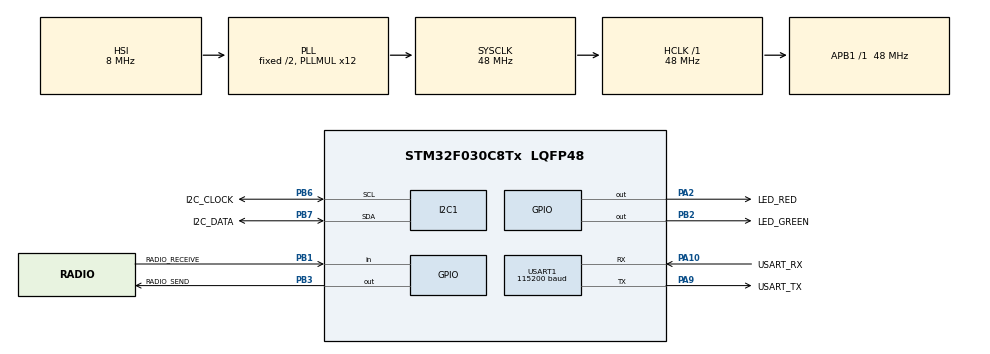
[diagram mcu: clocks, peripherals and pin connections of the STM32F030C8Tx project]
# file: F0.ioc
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Mcu.Family=STM32F0
USART1.BaudRate=115200
PA14.GPIO_Label=SWD_CLOCK
PB2.GPIO_Speed=GPIO_SPEED_FREQ_HIGH
PA2.GPIO_Speed=GPIO_SPEED_FREQ_HIGH
VP_RTC_VS_RTC_Activate.Mode=RTC_Enabled
PB6.GPIO_Label=I2C_CLOCK
RCC.SYSCLKSource=RCC_SYSCLKSOURCE_PLLCLK
ProjectManager.StackSize=0x400
TIM15.Prescaler=480
RCC.HCLKFreq_Value=48000000
PB6.Signal=I2C1_SCL
PB6.Mode=I2C
RCC.AHBFreq_Value=48000000
PB2.Signal=GPIO_Output
RCC.PLLMUL=RCC_PLL_MUL12
TIM15.Period=99
PA14.Mode=Serial_Wire
PB1.GPIO_Label=RADIO_RECEIVE
PA10.GPIO_Label=USART_RX
PB7.Signal=I2C1_SDA
PB7.GPIO_Label=I2C_DATA
Mcu.Package=LQFP48
PB1.Signal=GPIO_Input
PA2.GPIO_Label=LED_RED
PA10.Signal=USART1_RX
VP_RTC_VS_RTC_Calendar.Mode=RTC_Calendar
RCC.APB1TimFreq_Value=48000000
TIM16.Prescaler=48
NVIC.TIM15_IRQn=true\:0\:0\:false\:false\:true\:true\:true
PB3.GPIO_Label=RADIO_SEND
PA10.Mode=Asynchronous
PA9.GPIO_Label=USART_TX
VP_TIM16_VS_ClockSourceINT.Mode=Enable_Timer
NVIC.TIM16_IRQn=true\:0\:0\:false\:false\:true\:true\:true
USART1.VirtualMode-Asynchronous=VM_ASYNC
PA13.Signal=SYS_SWDIO
PA9.Mode=Asynchronous
ProjectManager.TargetToolchain=STM32CubeIDE
PA9.Signal=USART1_TX
I2C1.Timing=0x20303E5D
board=custom
TIM16.Period=9
RCC.I2c1ClockSelection=RCC_I2C1CLKSOURCE_SYSCLK
PA13.Mode=Serial_Wire
Mcu.Name=STM32F030C8Tx
PA13.GPIO_Label=SWD_IO
PA2.Signal=GPIO_Output
PB3.Signal=GPIO_Output
RCC.SYSCLKFreq_VALUE=48000000
PB7.Mode=I2C
VP_TIM15_VS_ClockSourceINT.Mode=Internal
PA14.Signal=SYS_SWCLK
PB2.GPIO_Label=LED_GREEN
ProjectManager.HeapSize=0x200
RCC.APB1Freq_Value=48000000

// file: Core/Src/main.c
/* USER CODE BEGIN Header */
/**
 ******************************************************************************
 * @file           : main.c
 * @brief          : Main program body
 ******************************************************************************
 * @attention
 *
 * <h2><center>&copy; Copyright (c) 2021 STMicroelectronics.
 * All rights reserved.</center></h2>
 *
 * This software component is licensed by ST under BSD 3-Clause license,
 * the "License"; You may not use this file except in compliance with the
 * License. You may obtain a copy of the License at:
 *                        opensource.org/licenses/BSD-3-Clause
 *
 ******************************************************************************
 */
/* USER CODE END Header */
#include "main.h"
#include "i2c.h"
#include "rtc.h"
#include "tim.h"
#include "usart.h"
#include "gpio.h"

/* USER CODE BEGIN Includes */

#include "RATmain.h"

/* USER CODE END Includes */

void SystemClock_Config(void);

int main(void)
{

  /* MCU Configuration--------------------------------------------------------*/

  /* Reset of all peripherals, Initializes the Flash interface and the Systick. */
  HAL_Init();

  /* Configure the system clock */
  SystemClock_Config();

  /* Initialize all configured peripherals */
  MX_GPIO_Init();
  MX_I2C1_Init();
  MX_USART1_UART_Init();
  MX_RTC_Init();
  MX_TIM15_Init();
  MX_TIM16_Init();
  /* USER CODE BEGIN 2 */

  //Own main file, for readabillity
  RATmain();

  /* USER CODE END 2 */

  /* Infinite loop */
	while (1)
	{

	}
}

void SystemClock_Config(void)
{
  RCC_OscInitTypeDef RCC_OscInitStruct = {0};
  RCC_ClkInitTypeDef RCC_ClkInitStruct = {0};
  RCC_PeriphCLKInitTypeDef PeriphClkInit = {0};

  /** Initializes the RCC Oscillators according to the specified parameters
  * in the RCC_OscInitTypeDef structure.
  */
  RCC_OscInitStruct.OscillatorType = RCC_OSCILLATORTYPE_HSI|RCC_OSCILLATORTYPE_LSI;
  RCC_OscInitStruct.HSIState = RCC_HSI_ON;
  RCC_OscInitStruct.HSICalibrationValue = RCC_HSICALIBRATION_DEFAULT;
  RCC_OscInitStruct.LSIState = RCC_LSI_ON;
  RCC_OscInitStruct.PLL.PLLState = RCC_PLL_ON;
  RCC_OscInitStruct.PLL.PLLSource = RCC_PLLSOURCE_HSI;
  RCC_OscInitStruct.PLL.PLLMUL = RCC_PLL_MUL12;
  RCC_OscInitStruct.PLL.PREDIV = RCC_PREDIV_DIV1;
  if (HAL_RCC_OscConfig(&RCC_OscInitStruct) != HAL_OK)
  {
    Error_Handler();
  }
  /** Initializes the CPU, AHB and APB buses clocks
  */
  RCC_ClkInitStruct.ClockType = RCC_CLOCKTYPE_HCLK|RCC_CLOCKTYPE_SYSCLK
                              |RCC_CLOCKTYPE_PCLK1;
  RCC_ClkInitStruct.SYSCLKSource = RCC_SYSCLKSOURCE_PLLCLK;
  RCC_ClkInitStruct.AHBCLKDivider = RCC_SYSCLK_DIV1;
  RCC_ClkInitStruct.APB1CLKDivider = RCC_HCLK_DIV1;

  if (HAL_RCC_ClockConfig(&RCC_ClkInitStruct, FLASH_LATENCY_1) != HAL_OK)
  {
    Error_Handler();
  }
  PeriphClkInit.PeriphClockSelection = RCC_PERIPHCLK_USART1|RCC_PERIPHCLK_I2C1
                              |RCC_PERIPHCLK_RTC;
  PeriphClkInit.Usart1ClockSelection = RCC_USART1CLKSOURCE_PCLK1;
  PeriphClkInit.I2c1ClockSelection = RCC_I2C1CLKSOURCE_SYSCLK;
  PeriphClkInit.RTCClockSelection = RCC_RTCCLKSOURCE_LSI;
  if (HAL_RCCEx_PeriphCLKConfig(&PeriphClkInit) != HAL_OK)
  {
    Error_Handler();
  }
}

void Error_Handler(void)
{
	__disable_irq();
	while (1)
	{
	}
}

/************************ (C) COPYRIGHT STMicroelectronics *****END OF FILE****/
